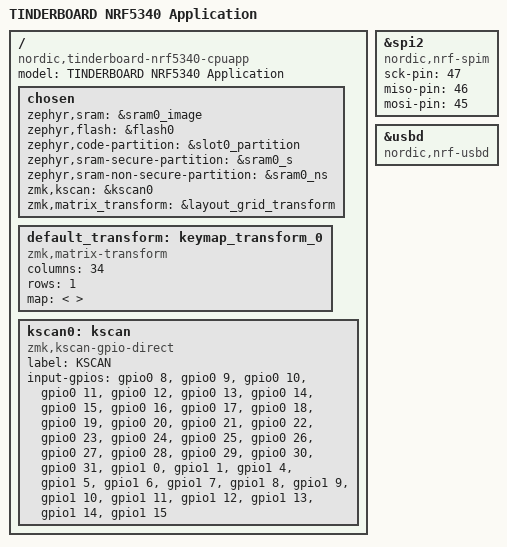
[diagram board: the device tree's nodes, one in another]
/*
 * Copyright (c) 2020 Nordic Semiconductor ASA
 *
 * SPDX-License-Identifier: Apache-2.0
 */

/dts-v1/;
#include <nordic/nrf5340_cpuapp_qkaa.dtsi>
#include "nrf5340_cpuapp_common.dts"
#include <dt-bindings/zmk/matrix_transform.h>

/ {
	model = "TINDERBOARD NRF5340 Application";
	compatible = "nordic,tinderboard-nrf5340-cpuapp";

	chosen {
		zephyr,sram = &sram0_image;
		zephyr,flash = &flash0;
		zephyr,code-partition = &slot0_partition;
		zephyr,sram-secure-partition = &sram0_s;
		zephyr,sram-non-secure-partition = &sram0_ns;
		zmk,kscan = &kscan0;
		zmk,matrix_transform = &layout_grid_transform;
	};

	
	default_transform: keymap_transform_0 {
		compatible = "zmk,matrix-transform";
		columns = <34>;
		rows = <1>;
		map = <
/*			RC(0,0)  RC(0,1)  RC(0,2)  RC(0,3)  RC(0,4)    RC(0,21) RC(0,20) RC(0,19) RC(0,18) RC(0,17)*/
/*			RC(0,5)  RC(0,6)  RC(0,7)  RC(0,8)  RC(0,9)    RC(0,26) RC(0,25) RC(0,24) RC(0,23) RC(0,22)*/
/*			RC(0,10) RC(0,11) RC(0,12) RC(0,13) RC(0,14)   RC(0,31) RC(0,30) RC(0,29) RC(0,28) RC(0,27)*/
/*			                           RC(0,15) RC(0,16)   RC(0,33) RC(0,32)*/
		>;
	};


	kscan0: kscan {
		compatible="zmk,kscan-gpio-direct";
		label = "KSCAN";
		input-gpios =
			<&gpio0 8  (GPIO_ACTIVE_HIGH | GPIO_PULL_DOWN)>,
			<&gpio0 9  (GPIO_ACTIVE_HIGH | GPIO_PULL_DOWN)>,
			<&gpio0 10 (GPIO_ACTIVE_HIGH | GPIO_PULL_DOWN)>,
			<&gpio0 11 (GPIO_ACTIVE_HIGH | GPIO_PULL_DOWN)>,
			<&gpio0 12 (GPIO_ACTIVE_HIGH | GPIO_PULL_DOWN)>,
			<&gpio0 13 (GPIO_ACTIVE_HIGH | GPIO_PULL_DOWN)>,
			<&gpio0 14 (GPIO_ACTIVE_HIGH | GPIO_PULL_DOWN)>,
			<&gpio0 15 (GPIO_ACTIVE_HIGH | GPIO_PULL_DOWN)>,
			<&gpio0 16 (GPIO_ACTIVE_HIGH | GPIO_PULL_DOWN)>,
			<&gpio0 17 (GPIO_ACTIVE_HIGH | GPIO_PULL_DOWN)>,
			<&gpio0 18 (GPIO_ACTIVE_HIGH | GPIO_PULL_DOWN)>,
			<&gpio0 19 (GPIO_ACTIVE_HIGH | GPIO_PULL_DOWN)>,
			<&gpio0 20 (GPIO_ACTIVE_HIGH | GPIO_PULL_DOWN)>,
			<&gpio0 21 (GPIO_ACTIVE_HIGH | GPIO_PULL_DOWN)>,
			<&gpio0 22 (GPIO_ACTIVE_HIGH | GPIO_PULL_DOWN)>,
			<&gpio0 23 (GPIO_ACTIVE_HIGH | GPIO_PULL_DOWN)>,
			<&gpio0 24 (GPIO_ACTIVE_HIGH | GPIO_PULL_DOWN)>,
			<&gpio0 25 (GPIO_ACTIVE_HIGH | GPIO_PULL_DOWN)>,
			<&gpio0 26 (GPIO_ACTIVE_HIGH | GPIO_PULL_DOWN)>,
			<&gpio0 27 (GPIO_ACTIVE_HIGH | GPIO_PULL_DOWN)>,
			<&gpio0 28 (GPIO_ACTIVE_HIGH | GPIO_PULL_DOWN)>,
			<&gpio0 29 (GPIO_ACTIVE_HIGH | GPIO_PULL_DOWN)>,
			<&gpio0 30 (GPIO_ACTIVE_HIGH | GPIO_PULL_DOWN)>,
			<&gpio0 31 (GPIO_ACTIVE_HIGH | GPIO_PULL_DOWN)>,
			<&gpio1 0  (GPIO_ACTIVE_HIGH | GPIO_PULL_DOWN)>,
			<&gpio1 1  (GPIO_ACTIVE_HIGH | GPIO_PULL_DOWN)>,
			<&gpio1 4  (GPIO_ACTIVE_HIGH | GPIO_PULL_DOWN)>,
			<&gpio1 5  (GPIO_ACTIVE_HIGH | GPIO_PULL_DOWN)>,
			<&gpio1 6  (GPIO_ACTIVE_HIGH | GPIO_PULL_DOWN)>,
			<&gpio1 7  (GPIO_ACTIVE_HIGH | GPIO_PULL_DOWN)>,
			<&gpio1 8  (GPIO_ACTIVE_HIGH | GPIO_PULL_DOWN)>,
			<&gpio1 9  (GPIO_ACTIVE_HIGH | GPIO_PULL_DOWN)>,
			<&gpio1 10 (GPIO_ACTIVE_HIGH | GPIO_PULL_DOWN)>,
			<&gpio1 11 (GPIO_ACTIVE_HIGH | GPIO_PULL_DOWN)>,
			<&gpio1 12 (GPIO_ACTIVE_HIGH | GPIO_PULL_DOWN)>,
			<&gpio1 13 (GPIO_ACTIVE_HIGH | GPIO_PULL_DOWN)>,
			<&gpio1 14 (GPIO_ACTIVE_HIGH | GPIO_PULL_DOWN)>,
			<&gpio1 15 (GPIO_ACTIVE_HIGH | GPIO_PULL_DOWN)>
			;
	};

};

&spi2 {
	compatible = "nordic,nrf-spim";
	status = "okay";
	sck-pin = <47>;
	miso-pin = <46>;
	mosi-pin = <45>;
};

zephyr_udc0: &usbd {
	compatible = "nordic,nrf-usbd";
	status = "okay";
};
